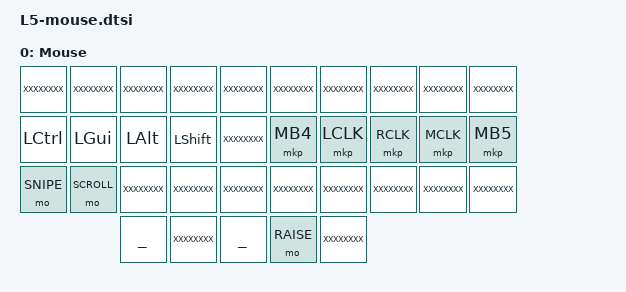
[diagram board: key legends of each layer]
/**
 *
 */

/ {
  keymap {
    compatible = "zmk,keymap";

	mouse_layer {
		label = "Mouse";
		bindings = <
//	╭───────────────┬───────────────┬───────────────┬───────────────┬───────────────╮   ╭───────────────┬───────────────┬───────────────┬───────────────┬───────────────╮
	XXXXXXXX		XXXXXXXX    	XXXXXXXX		XXXXXXXX		XXXXXXXX			XXXXXXXX        XXXXXXXX     	XXXXXXXX        XXXXXXXX        XXXXXXXX
//	├───────────────┼───────────────┼───────────────┼───────────────┼───────────────┤   ├───────────────├───────────────┼───────────────┼───────────────┼───────────────┤
	&kp LCTRL		&kp LGUI    	&kp LALT		&kp LSHFT		XXXXXXXX			&mkp MB4        &mkp LCLK     	&mkp RCLK        &mkp MCLK      &mkp MB5
//	├───────────────┼───────────────┼───────────────┼───────────────┼───────────────┤   ├───────────────├───────────────┼───────────────┼───────────────┼───────────────┤
	&mo SNIPE		&mo SCROLL    	XXXXXXXX		XXXXXXXX		XXXXXXXX            XXXXXXXX        XXXXXXXX     	XXXXXXXX        XXXXXXXX        XXXXXXXX 
//	╰───────────────┴───────────────┼───────────────┼───────────────┼───────────────┤   ├───────────────├───────────────┼───────────────┼───────────────┴───────────────╯
	       							________		XXXXXXXX        ________           	&mo RAISE		XXXXXXXX
//                                                  ╰───────────────┴───────────────╯   ╰───────────────┴───────────────╯
			>;
		};
	};
};
